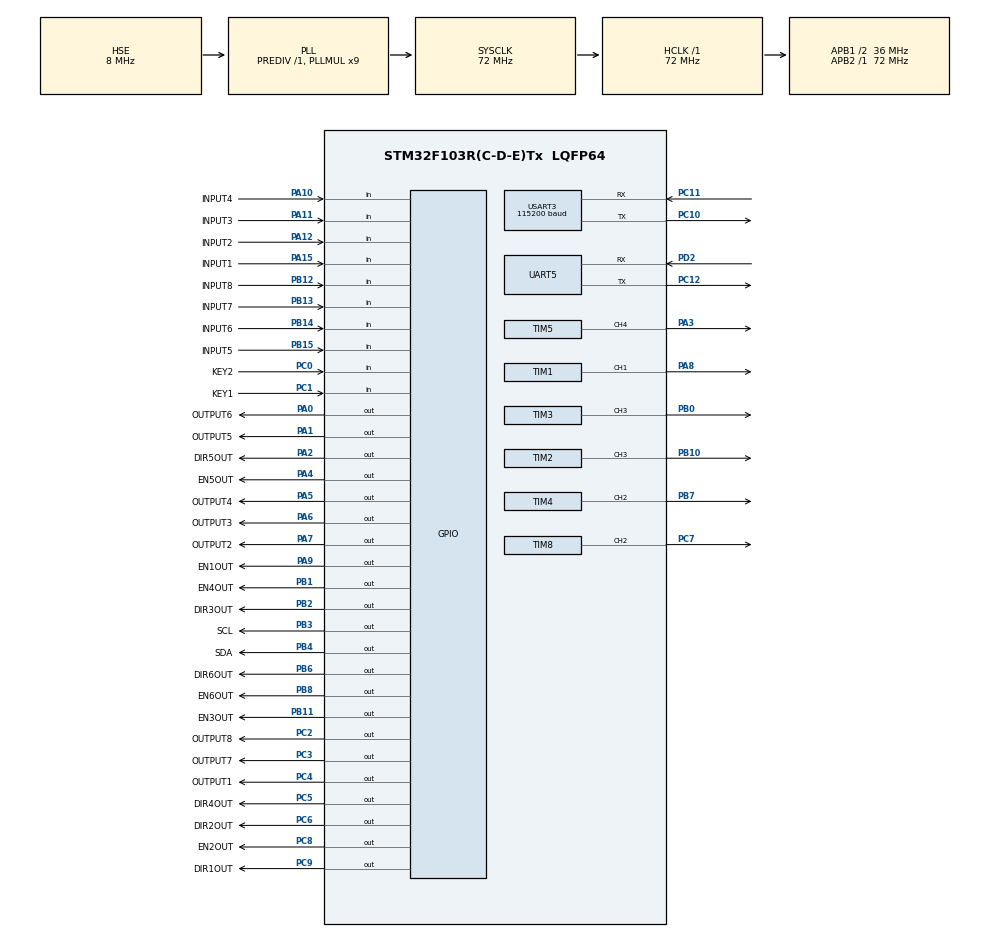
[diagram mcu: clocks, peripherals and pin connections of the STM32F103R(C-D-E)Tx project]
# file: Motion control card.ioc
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Dma.Request0=USART3_RX
Dma.Request1=USART3_TX
Dma.USART3_RX.0.Direction=DMA_PERIPH_TO_MEMORY
Dma.USART3_RX.0.Instance=DMA1_Channel3
Dma.USART3_RX.0.MemDataAlignment=DMA_MDATAALIGN_BYTE
Dma.USART3_RX.0.MemInc=DMA_MINC_ENABLE
Dma.USART3_RX.0.Mode=DMA_NORMAL
Dma.USART3_RX.0.PeriphDataAlignment=DMA_PDATAALIGN_BYTE
Dma.USART3_RX.0.PeriphInc=DMA_PINC_DISABLE
Dma.USART3_RX.0.Priority=DMA_PRIORITY_HIGH
Dma.USART3_TX.1.Direction=DMA_MEMORY_TO_PERIPH
Dma.USART3_TX.1.Instance=DMA1_Channel2
Dma.USART3_TX.1.MemDataAlignment=DMA_MDATAALIGN_BYTE
Dma.USART3_TX.1.MemInc=DMA_MINC_ENABLE
Dma.USART3_TX.1.Mode=DMA_NORMAL
Dma.USART3_TX.1.PeriphDataAlignment=DMA_PDATAALIGN_BYTE
Dma.USART3_TX.1.PeriphInc=DMA_PINC_DISABLE
Dma.USART3_TX.1.Priority=DMA_PRIORITY_LOW
Mcu.Family=STM32F1
Mcu.Name=STM32F103R(C-D-E)Tx
Mcu.Package=LQFP64
NVIC.DMA1_Channel2_IRQn=true\:0\:0\:false\:false\:true\:false\:true\:true
NVIC.DMA1_Channel3_IRQn=true\:0\:0\:false\:false\:true\:false\:true\:true
NVIC.PVD_IRQn=true\:0\:0\:false\:false\:true\:true\:true\:true
NVIC.PriorityGroup=NVIC_PRIORITYGROUP_4
NVIC.TIM1_UP_IRQn=true\:0\:0\:false\:false\:true\:true\:true\:true
NVIC.TIM2_IRQn=true\:0\:0\:false\:false\:true\:true\:true\:true
NVIC.TIM3_IRQn=true\:0\:0\:false\:false\:true\:true\:true\:true
NVIC.TIM4_IRQn=true\:0\:0\:false\:false\:true\:true\:true\:true
NVIC.TIM5_IRQn=true\:0\:0\:false\:false\:true\:true\:true\:true
NVIC.TIM8_UP_IRQn=true\:0\:0\:false\:false\:true\:true\:true\:true
NVIC.USART3_IRQn=true\:0\:0\:false\:false\:true\:true\:true\:true
PA0-WKUP.GPIO_Label=OUTPUT6
PA0-WKUP.GPIO_PuPd=GPIO_PULLUP
PA0-WKUP.GPIO_Speed=GPIO_SPEED_FREQ_HIGH
PA0-WKUP.Signal=GPIO_Output
PA1.GPIO_Label=OUTPUT5
PA1.GPIO_PuPd=GPIO_PULLUP
PA1.GPIO_Speed=GPIO_SPEED_FREQ_HIGH
PA1.Signal=GPIO_Output
PA10.GPIO_Label=INPUT4
PA10.GPIO_PuPd=GPIO_PULLUP
PA10.Signal=GPIO_Input
PA11.GPIO_Label=INPUT3
PA11.GPIO_PuPd=GPIO_PULLUP
PA11.Signal=GPIO_Input
PA12.GPIO_Label=INPUT2
PA12.GPIO_PuPd=GPIO_PULLUP
PA12.Signal=GPIO_Input
PA13.Mode=Serial_Wire
PA13.Signal=SYS_JTMS-SWDIO
PA14.Mode=Serial_Wire
PA14.Signal=SYS_JTCK-SWCLK
PA15.GPIO_Label=INPUT1
PA15.GPIO_PuPd=GPIO_PULLUP
PA15.Signal=GPIO_Input
PA2.GPIO_Label=DIR5OUT
PA2.GPIO_Speed=GPIO_SPEED_FREQ_HIGH
PA2.PinState=GPIO_PIN_RESET
PA2.Signal=GPIO_Output
PA3.GPIO_Speed=GPIO_SPEED_FREQ_HIGH
PA3.Signal=S_TIM5_CH4
PA4.GPIO_Label=EN5OUT
PA4.GPIO_Speed=GPIO_SPEED_FREQ_HIGH
PA4.PinState=GPIO_PIN_RESET
PA4.Signal=GPIO_Output
PA5.GPIO_Label=OUTPUT4
PA5.GPIO_PuPd=GPIO_PULLUP
PA5.GPIO_Speed=GPIO_SPEED_FREQ_HIGH
PA5.PinState=GPIO_PIN_RESET
PA5.Signal=GPIO_Output
PA6.GPIO_Label=OUTPUT3
PA6.GPIO_PuPd=GPIO_PULLUP
PA6.GPIO_Speed=GPIO_SPEED_FREQ_HIGH
PA6.Signal=GPIO_Output
PA7.GPIO_Label=OUTPUT2
PA7.GPIO_PuPd=GPIO_PULLUP
PA7.GPIO_Speed=GPIO_SPEED_FREQ_HIGH
PA7.Signal=GPIO_Output
PA8.GPIO_Speed=GPIO_SPEED_FREQ_HIGH
PA8.Signal=S_TIM1_CH1
PA9.GPIO_Label=EN1OUT
PA9.GPIO_Speed=GPIO_SPEED_FREQ_HIGH
PA9.PinState=GPIO_PIN_RESET
PA9.Signal=GPIO_Output
PB0.GPIO_Speed=GPIO_SPEED_FREQ_HIGH
PB0.Signal=S_TIM3_CH3
PB1.GPIO_Label=EN4OUT
PB1.GPIO_Speed=GPIO_SPEED_FREQ_HIGH
PB1.PinState=GPIO_PIN_RESET
PB1.Signal=GPIO_Output
PB10.GPIO_Speed=GPIO_SPEED_FREQ_HIGH
PB10.Signal=S_TIM2_CH3
PB11.GPIO_Label=EN3OUT
PB11.GPIO_PuPd=GPIO_PULLUP
PB11.GPIO_Speed=GPIO_SPEED_FREQ_HIGH
PB11.PinState=GPIO_PIN_RESET
PB11.Signal=GPIO_Output
PB12.GPIO_Label=INPUT8
PB12.GPIO_PuPd=GPIO_PULLUP
PB12.Signal=GPIO_Input
PB13.GPIO_Label=INPUT7
PB13.GPIO_PuPd=GPIO_PULLUP
PB13.Signal=GPIO_Input
PB14.GPIO_Label=INPUT6
PB14.GPIO_PuPd=GPIO_PULLUP
PB14.Signal=GPIO_Input
PB15.GPIO_Label=INPUT5
PB15.GPIO_PuPd=GPIO_PULLUP
PB15.Signal=GPIO_Input
PB2.GPIO_Label=DIR3OUT
PB2.GPIO_Speed=GPIO_SPEED_FREQ_HIGH
PB2.PinState=GPIO_PIN_RESET
PB2.Signal=GPIO_Output
PB3.GPIO_Label=SCL
PB3.GPIO_PuPd=GPIO_PULLUP
PB3.GPIO_Speed=GPIO_SPEED_FREQ_HIGH
PB3.PinState=GPIO_PIN_RESET
PB3.Signal=GPIO_Output
PB4.GPIO_Label=SDA
PB4.GPIO_PuPd=GPIO_PULLUP
PB4.GPIO_Speed=GPIO_SPEED_FREQ_HIGH
PB4.Signal=GPIO_Output
PB6.GPIO_Label=DIR6OUT
PB6.GPIO_Speed=GPIO_SPEED_FREQ_HIGH
PB6.PinState=GPIO_PIN_RESET
PB6.Signal=GPIO_Output
PB7.GPIO_Speed=GPIO_SPEED_FREQ_HIGH
PB7.Signal=S_TIM4_CH2
PB8.GPIO_Label=EN6OUT
PB8.GPIO_ModeDefaultOutputPP=GPIO_MODE_OUTPUT_PP
PB8.GPIO_PuPd=GPIO_NOPULL
PB8.GPIO_Speed=GPIO_SPEED_FREQ_HIGH
PB8.PinState=GPIO_PIN_RESET
PB8.Signal=GPIO_Output
PC0.GPIO_Label=KEY2
PC0.GPIO_PuPd=GPIO_PULLUP
PC0.Signal=GPIO_Input
PC1.GPIO_Label=KEY1
PC1.GPIO_PuPd=GPIO_PULLUP
PC1.Signal=GPIO_Input
PC10.Mode=Asynchronous
PC10.Signal=USART3_TX
PC11.Mode=Asynchronous
PC11.Signal=USART3_RX
PC12.Mode=Asynchronous
PC12.Signal=UART5_TX
PC14-OSC32_IN.Mode=LSE-External-Oscillator
PC14-OSC32_IN.Signal=RCC_OSC32_IN
PC15-OSC32_OUT.Mode=LSE-External-Oscillator
PC15-OSC32_OUT.Signal=RCC_OSC32_OUT
PC2.GPIO_Label=OUTPUT8
PC2.GPIO_PuPd=GPIO_PULLUP
PC2.GPIO_Speed=GPIO_SPEED_FREQ_HIGH
PC2.Signal=GPIO_Output
PC3.GPIO_Label=OUTPUT7
PC3.GPIO_PuPd=GPIO_PULLUP
PC3.GPIO_Speed=GPIO_SPEED_FREQ_HIGH
PC3.Signal=GPIO_Output
PC4.GPIO_Label=OUTPUT1
PC4.GPIO_PuPd=GPIO_PULLUP
PC4.GPIO_Speed=GPIO_SPEED_FREQ_HIGH
PC4.PinState=GPIO_PIN_RESET
PC4.Signal=GPIO_Output
PC5.GPIO_Label=DIR4OUT
PC5.GPIO_Speed=GPIO_SPEED_FREQ_HIGH
PC5.PinState=GPIO_PIN_RESET
PC5.Signal=GPIO_Output
PC6.GPIO_Label=DIR2OUT
PC6.GPIO_Speed=GPIO_SPEED_FREQ_HIGH
PC6.PinState=GPIO_PIN_RESET
PC6.Signal=GPIO_Output
PC7.GPIO_Speed=GPIO_SPEED_FREQ_HIGH
PC7.Signal=S_TIM8_CH2
PC8.GPIO_Label=EN2OUT
PC8.GPIO_Speed=GPIO_SPEED_FREQ_HIGH
PC8.PinState=GPIO_PIN_RESET
PC8.Signal=GPIO_Output
PC9.GPIO_Label=DIR1OUT
PC9.GPIO_Speed=GPIO_SPEED_FREQ_HIGH
PC9.PinState=GPIO_PIN_RESET
PC9.Signal=GPIO_Output
PD0-OSC_IN.Mode=HSE-External-Oscillator
PD0-OSC_IN.Signal=RCC_OSC_IN
PD1-OSC_OUT.Mode=HSE-External-Oscillator
PD1-OSC_OUT.Signal=RCC_OSC_OUT
PD2.Mode=Asynchronous
PD2.Signal=UART5_RX
ProjectManager.HeapSize=0x200
ProjectManager.StackSize=0x400
ProjectManager.TargetToolchain=MDK-ARM V5.32
RCC.AHBFreq_Value=72000000
RCC.APB1CLKDivider=RCC_HCLK_DIV2
RCC.APB1Freq_Value=36000000
RCC.APB1TimFreq_Value=72000000
RCC.APB2Freq_Value=72000000
RCC.APB2TimFreq_Value=72000000
RCC.HCLKFreq_Value=72000000
RCC.PLLMUL=RCC_PLL_MUL9
RCC.PLLSourceVirtual=RCC_PLLSOURCE_HSE
RCC.SYSCLKFreq_VALUE=72000000
RCC.SYSCLKSource=RCC_SYSCLKSOURCE_PLLCLK
RCC.USBFreq_Value=72000000
SH.S_TIM1_CH1.0=TIM1_CH1,PWM Generation1 CH1
SH.S_TIM2_CH3.0=TIM2_CH3,PWM Generation3 CH3
SH.S_TIM3_CH3.0=TIM3_CH3,PWM Generation3 CH3
SH.S_TIM4_CH2.0=TIM4_CH2,PWM Generation2 CH2
SH.S_TIM5_CH4.0=TIM5_CH4,PWM Generation4 CH4
SH.S_TIM8_CH2.0=TIM8_CH2,PWM Generation2 CH2
TIM1.AutoReloadPreload=TIM_AUTORELOAD_PRELOAD_ENABLE
TIM1.Channel-PWM\ Generation1\ CH1=TIM_CHANNEL_1
TIM1.OCIdleState_1=TIM_OCIDLESTATE_RESET
TIM1.OCPolarity_1=TIM_OCPOLARITY_HIGH
TIM1.Period=200-1
TIM1.Prescaler=72-1
TIM1.Pulse-PWM\ Generation1\ CH1=0
TIM2.AutoReloadPreload=TIM_AUTORELOAD_PRELOAD_ENABLE
TIM2.Channel-PWM\ Generation3\ CH3=TIM_CHANNEL_3
TIM2.Period=200-1
TIM2.Prescaler=72-1
TIM3.AutoReloadPreload=TIM_AUTORELOAD_PRELOAD_ENABLE
TIM3.Channel-PWM\ Generation3\ CH3=TIM_CHANNEL_3
TIM3.Period=200-1
TIM3.Prescaler=72-1
TIM4.AutoReloadPreload=TIM_AUTORELOAD_PRELOAD_ENABLE
TIM4.Channel-PWM\ Generation2\ CH2=TIM_CHANNEL_2
TIM4.Period=200-1
TIM4.Prescaler=72-1
TIM5.AutoReloadPreload=TIM_AUTORELOAD_PRELOAD_ENABLE
TIM5.Channel-PWM\ Generation4\ CH4=TIM_CHANNEL_4
TIM5.Period=200-1
TIM5.Prescaler=72-1
TIM8.AutoReloadPreload=TIM_AUTORELOAD_PRELOAD_ENABLE
TIM8.Channel-PWM\ Generation2\ CH2=TIM_CHANNEL_2
TIM8.Period=200-1
TIM8.Prescaler=72-1
UART5.VirtualMode=Asynchronous
USART3.BaudRate=115200
USART3.VirtualMode=VM_ASYNC
VP_TIM1_VS_ClockSourceINT.Mode=Internal
VP_TIM2_VS_ClockSourceINT.Mode=Internal
VP_TIM8_VS_ClockSourceINT.Mode=Internal
board=custom

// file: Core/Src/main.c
/* USER CODE BEGIN Header */
/**
 ******************************************************************************
 * @file           : main.c
 * @brief          : Main program body
 ******************************************************************************
 * @attention
 *
 * Copyright (c) 2025 STMicroelectronics.
 * All rights reserved.
 *
 * This software is licensed under terms that can be found in the LICENSE file
 * in the root directory of this software component.
 * If no LICENSE file comes with this software, it is provided AS-IS.
 *
 ******************************************************************************
 */
/* USER CODE END Header */
#include "main.h"
#include "dma.h"
#include "tim.h"
#include "usart.h"
#include "gpio.h"

/* USER CODE BEGIN Includes */
#include "include.h"
/* USER CODE END Includes */

void SystemClock_Config(void);

int main(void)
{

  /* MCU Configuration--------------------------------------------------------*/

  /* Reset of all peripherals, Initializes the Flash interface and the Systick. */
  HAL_Init();

  /* Configure the system clock */
  SystemClock_Config();

  /* Initialize all configured peripherals */
  MX_GPIO_Init();
  MX_DMA_Init();
  MX_TIM1_Init();
  MX_TIM2_Init();
  MX_TIM8_Init();
  MX_UART5_Init();
  MX_USART3_UART_Init();
  MX_TIM3_Init();
  MX_TIM5_Init();
  MX_TIM4_Init();
  /* USER CODE BEGIN 2 */
  OUTPUT_init();
  PVD_Config();
  fixed_math_init();     // 初始化定点数查表 (平方根/正弦)
  torque_comp_init();    // 初始化力矩补偿默认参数
  Scheduler_Setup();     // 初始化任务调度
  HAL_Delay(10000);      // 网口模块需要10秒准备
  Serial_Init();
  /* USER CODE END 2 */

  /* Infinite loop */
  /* USER CODE BEGIN WHILE */
  // Motor_Set(1, 2, 1, 3200, 800, 3200, 2400);
  // Motor_Set(2, 2, 1, 1600, 200, 3200, 100);
  // Motor_Set(3, 2, 1, 1600, 200, 3200, 100);
  // Motor_Set(4, 2, 1, 1600, 200, 3200, 100);
  // Motor_Set(5, 2, 1, 1600, 200, 3200, 100);
  // Motor_Set(6, 2, 1, 1600, 200, 3200, 100);
  while (1)
  {
    /* USER CODE END WHILE */

    /* USER CODE BEGIN 3 */

    // HAL_Delay(8000);
    // for (int i = 0; i < 8; i++)
    //   OUTPUT_control(i + 1, 1);
    // HAL_Delay(500);
    // for (int i = 0; i < 8; i++)
    //   OUTPUT_control(i+1, 0);
    // HAL_Delay(500);
    Scheduler_Run(); // 任务调度
  }
  /* USER CODE END 3 */
}

void SystemClock_Config(void)
{
  RCC_OscInitTypeDef RCC_OscInitStruct = {0};
  RCC_ClkInitTypeDef RCC_ClkInitStruct = {0};

  /** Initializes the RCC Oscillators according to the specified parameters
   * in the RCC_OscInitTypeDef structure.
   */
  RCC_OscInitStruct.OscillatorType = RCC_OSCILLATORTYPE_HSE;
  RCC_OscInitStruct.HSEState = RCC_HSE_ON;
  RCC_OscInitStruct.HSEPredivValue = RCC_HSE_PREDIV_DIV1;
  RCC_OscInitStruct.HSIState = RCC_HSI_ON;
  RCC_OscInitStruct.PLL.PLLState = RCC_PLL_ON;
  RCC_OscInitStruct.PLL.PLLSource = RCC_PLLSOURCE_HSE;
  RCC_OscInitStruct.PLL.PLLMUL = RCC_PLL_MUL9;
  if (HAL_RCC_OscConfig(&RCC_OscInitStruct) != HAL_OK)
  {
    Error_Handler();
  }

  /** Initializes the CPU, AHB and APB buses clocks
   */
  RCC_ClkInitStruct.ClockType = RCC_CLOCKTYPE_HCLK | RCC_CLOCKTYPE_SYSCLK | RCC_CLOCKTYPE_PCLK1 | RCC_CLOCKTYPE_PCLK2;
  RCC_ClkInitStruct.SYSCLKSource = RCC_SYSCLKSOURCE_PLLCLK;
  RCC_ClkInitStruct.AHBCLKDivider = RCC_SYSCLK_DIV1;
  RCC_ClkInitStruct.APB1CLKDivider = RCC_HCLK_DIV2;
  RCC_ClkInitStruct.APB2CLKDivider = RCC_HCLK_DIV1;

  if (HAL_RCC_ClockConfig(&RCC_ClkInitStruct, FLASH_LATENCY_2) != HAL_OK)
  {
    Error_Handler();
  }
}

void Error_Handler(void)
{
  __disable_irq();
  while (1)
  {
  }
}
